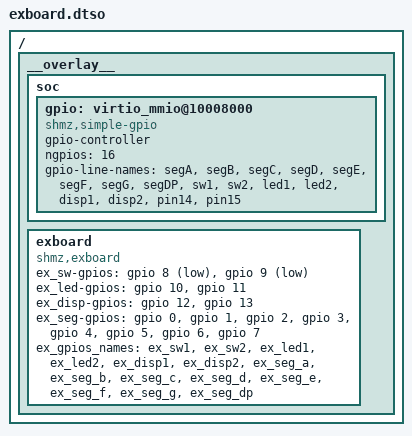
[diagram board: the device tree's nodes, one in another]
// #define GPIO_ACTIVE_HIGH 0 // from dt-bindings/gpio/gpio.h
#include <dt-bindings/gpio/gpio.h>
/dts-v1/;
/plugin/;

/ {
    __overlay__ {

        // ----------------------------------------------------
        // (1) カスタム GPIO コントローラーの定義とphandle設定
        // ----------------------------------------------------
        soc {

            // 既存の virtio_mmio@10008000 ノードをカスタム GPIO コントローラーとして上書き
            // ラベル（phandle）を「gpio」として設定することで、他のノードから &gpio で参照可能にする
            gpio: virtio_mmio@10008000 {

                compatible = "shmz,simple-gpio";

                // 既存の割り込みとアドレス定義を利用
                // interrupts = <0x08>;
                // reg = <0x00 0x10008000 0x00 0x1000>;

                // GPIOコントローラーとして機能させるプロパティ
                gpio-controller;
                #gpio-cells = <2>;
                ngpios = <16>; // DTSでピン番号が15番まで使われているため、この値は適切です。
                status = "okay";
		gpio-line-names = "segA", "segB", "segC", "segD",
                                  "segE", "segF", "segG", "segDP",
                                  "sw1", "sw2", "led1", "led2",
                                  "disp1", "disp2", "pin14", "pin15";

            };
        };

        // ----------------------------------------------------
        // (2) カスタムボード exboard の定義を追加
        // ----------------------------------------------------

        // exboard ノードをルートノード (/) の直下に追加
        exboard {
            compatible = "shmz,exboard";
            status = "okay";

            // <&gpio 2 GPIO_ACTIVE_LOW> の形式: <phandle ピン番号 フラグ>
            ex_sw-gpios = <&gpio 8 0x01>,
                          <&gpio 9 0x01>; // 0x01 = GPIO_ACTIVE_LOW

            // ex_led-gpios (GPIOピン 4, 9)
            ex_led-gpios = <&gpio 10 0x00>,
                           <&gpio 11 0x00>; // 0x00 = GPIO_ACTIVE_HIGH (デフォルト値)

            // ex_disp-gpios (GPIOピン 7, 8)
            ex_disp-gpios = <&gpio 12 0x00>,
                            <&gpio 13 0x00>;

            ex_seg-gpios = <&gpio 0 0x00>, <&gpio 1 0x00>,
                           <&gpio 2 0x00>, <&gpio 3 0x00>,
                           <&gpio 4 0x00>, <&gpio 5 0x00>,
                           <&gpio 6 0x00>, <&gpio 7 0x00>;

            ex_gpios_names = "ex_sw1", "ex_sw2",
                             "ex_led1", "ex_led2",
                             "ex_disp1", "ex_disp2",
                             "ex_seg_a", "ex_seg_b",
                             "ex_seg_c", "ex_seg_d",
                             "ex_seg_e", "ex_seg_f",
                             "ex_seg_g", "ex_seg_dp";

        }; // end exboard
    }; // end __overlay__
}; // end /
